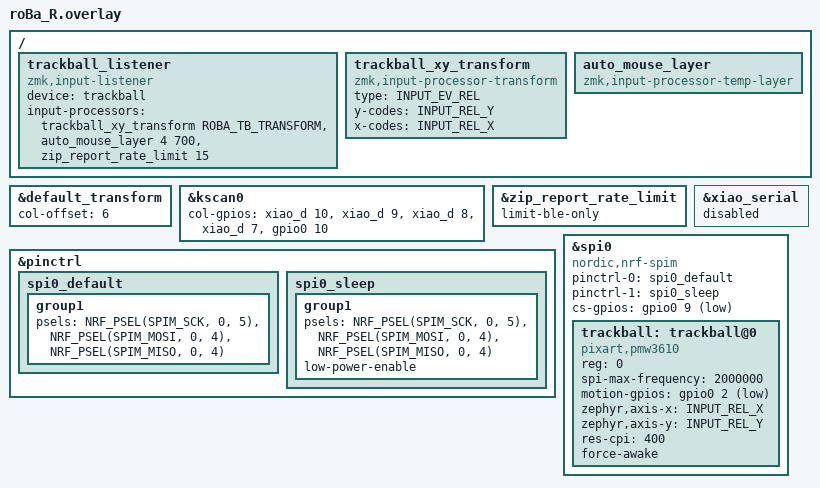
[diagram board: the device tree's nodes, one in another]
#include "roBa.dtsi"
#include <zephyr/dt-bindings/input/input-event-codes.h>
#include <dt-bindings/zmk/input_transform.h>
#include <input/processors/report_rate_limit.dtsi>

#define ROBA_TB_ROT_0 0
#define ROBA_TB_ROT_90 (INPUT_TRANSFORM_XY_SWAP | INPUT_TRANSFORM_X_INVERT)
#define ROBA_TB_ROT_180 (INPUT_TRANSFORM_X_INVERT | INPUT_TRANSFORM_Y_INVERT)
#define ROBA_TB_ROT_270 (INPUT_TRANSFORM_XY_SWAP | INPUT_TRANSFORM_Y_INVERT)

#define ROBA_TB_TRANSFORM ROBA_TB_ROT_90

&default_transform {
    col-offset = <6>;
};

&kscan0 {
        col-gpios
            = <&xiao_d 10 GPIO_ACTIVE_HIGH>
            , <&xiao_d 9 GPIO_ACTIVE_HIGH> 
            , <&xiao_d 8 GPIO_ACTIVE_HIGH> 
            , <&xiao_d 7 GPIO_ACTIVE_HIGH> 
            , <&gpio0 10 GPIO_ACTIVE_HIGH>
            ;
};

/ {
    trackball_listener: trackball_listener {
        compatible = "zmk,input-listener";
        device = <&trackball>;
        input-processors = <&trackball_xy_transform ROBA_TB_TRANSFORM &auto_mouse_layer 4 700 &zip_report_rate_limit 15>;

    };

    trackball_xy_transform: trackball_xy_transform {
        compatible = "zmk,input-processor-transform";
        #input-processor-cells = <1>;
        type = <INPUT_EV_REL>;
        y-codes = <INPUT_REL_Y>;
        x-codes = <INPUT_REL_X>;
    };

    auto_mouse_layer: auto_mouse_layer {
        compatible = "zmk,input-processor-temp-layer";
        #input-processor-cells = <2>;
    };
};

&zip_report_rate_limit {
    limit-ble-only;
};

&pinctrl {
    spi0_default: spi0_default {
        group1 {
            psels = <NRF_PSEL(SPIM_SCK, 0, 5)>,
                <NRF_PSEL(SPIM_MOSI, 0, 4)>,
                <NRF_PSEL(SPIM_MISO, 0, 4)>;
        };
    };

    spi0_sleep: spi0_sleep {
        group1 {
            psels = <NRF_PSEL(SPIM_SCK, 0, 5)>,
                <NRF_PSEL(SPIM_MOSI, 0, 4)>,
                <NRF_PSEL(SPIM_MISO, 0, 4)>;
            low-power-enable;
        };
    };
};

&xiao_serial { status = "disabled"; };

&spi0 {
    status = "okay";
    compatible = "nordic,nrf-spim";
    pinctrl-0 = <&spi0_default>;
    pinctrl-1 = <&spi0_sleep>;
    pinctrl-names = "default", "sleep";
    cs-gpios = <&gpio0 9 GPIO_ACTIVE_LOW>;

    trackball: trackball@0 {
        status = "okay";
        compatible = "pixart,pmw3610";
        reg = <0>;
        spi-max-frequency = <2000000>;
        motion-gpios = <&gpio0 2 (GPIO_ACTIVE_LOW | GPIO_PULL_UP)>;
        zephyr,axis-x = <INPUT_REL_X>;
        zephyr,axis-y = <INPUT_REL_Y>;
        res-cpi = <400>;
        force-awake;
    };
};
